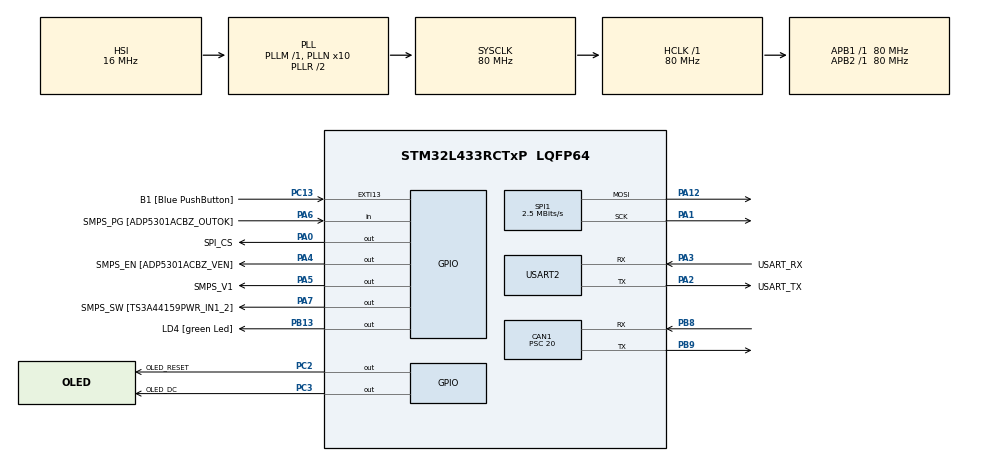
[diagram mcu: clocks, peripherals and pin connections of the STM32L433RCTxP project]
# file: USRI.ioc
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CAN1.BS1=CAN_BS1_14TQ
CAN1.CalculateBaudRate=250000
CAN1.CalculateTimeBit=4000.00
CAN1.CalculateTimeQuantum=250.0
CAN1.Prescaler=20
Mcu.Family=STM32L4
Mcu.Name=STM32L433RCTxP
Mcu.Package=LQFP64
NVIC.CAN1_RX0_IRQn=true\:0\:0\:false\:false\:true\:true\:true
NVIC.PriorityGroup=NVIC_PRIORITYGROUP_4
PA0.GPIO_Label=SPI_CS
PA0.Signal=GPIO_Output
PA1.Mode=TX_Only_Simplex_Unidirect_Master
PA1.Signal=SPI1_SCK
PA12.Mode=TX_Only_Simplex_Unidirect_Master
PA12.Signal=SPI1_MOSI
PA13\ (JTMS-SWDIO).GPIO_Label=TMS
PA13\ (JTMS-SWDIO).Mode=Serial_Wire
PA13\ (JTMS-SWDIO).Signal=SYS_JTMS-SWDIO
PA14\ (JTCK-SWCLK).GPIO_Label=TCK
PA14\ (JTCK-SWCLK).Mode=Serial_Wire
PA14\ (JTCK-SWCLK).Signal=SYS_JTCK-SWCLK
PA2.GPIO_Label=USART_TX
PA2.GPIO_Mode=GPIO_MODE_AF_PP
PA2.GPIO_PuPd=GPIO_NOPULL
PA2.GPIO_Speed=GPIO_SPEED_FREQ_VERY_HIGH
PA2.Mode=Asynchronous
PA2.Signal=USART2_TX
PA3.GPIO_Label=USART_RX
PA3.GPIO_Mode=GPIO_MODE_AF_PP
PA3.GPIO_PuPd=GPIO_NOPULL
PA3.GPIO_Speed=GPIO_SPEED_FREQ_VERY_HIGH
PA3.Mode=Asynchronous
PA3.Signal=USART2_RX
PA4.GPIO_Label=SMPS_EN [ADP5301ACBZ_VEN]
PA4.Signal=GPIO_Output
PA5.GPIO_Label=SMPS_V1
PA5.GPIO_ModeDefaultOutputPP=GPIO_MODE_OUTPUT_PP
PA5.GPIO_PuPd=GPIO_NOPULL
PA5.GPIO_Speed=GPIO_SPEED_FREQ_LOW
PA5.Signal=GPIO_Output
PA6.GPIO_Label=SMPS_PG [ADP5301ACBZ_OUTOK]
PA6.GPIO_PuPd=GPIO_PULLUP
PA6.Signal=GPIO_Input
PA7.GPIO_Label=SMPS_SW [TS3A44159PWR_IN1_2]
PA7.Signal=GPIO_Output
PB13.GPIO_Label=LD4 [green Led]
PB13.Signal=GPIO_Output
PB3\ (JTDO-TRACESWO).GPIO_Label=SWO
PB3\ (JTDO-TRACESWO).Signal=SYS_JTDO-SWO
PB8.Mode=CAN_Activate
PB8.Signal=CAN1_RX
PB9.Mode=CAN_Activate
PB9.Signal=CAN1_TX
PC13.GPIO_Label=B1 [Blue PushButton]
PC13.GPIO_ModeDefaultEXTI=GPIO_MODE_IT_FALLING
PC13.GPIO_PuPd=GPIO_NOPULL
PC13.Signal=GPXTI13
PC14-OSC32_IN\ (PC14).Mode=LSE-External-Oscillator
PC14-OSC32_IN\ (PC14).Signal=RCC_OSC32_IN
PC15-OSC32_OUT\ (PC15).Mode=LSE-External-Oscillator
PC15-OSC32_OUT\ (PC15).Signal=RCC_OSC32_OUT
PC2.GPIO_Label=OLED_RESET
PC2.Signal=GPIO_Output
PC3.GPIO_Label=OLED_DC
PC3.Signal=GPIO_Output
PH0-OSC_IN\ (PH0).GPIO_Label=MCO
PH0-OSC_IN\ (PH0).Mode=HSE-External-Clock-Source
PH0-OSC_IN\ (PH0).Signal=RCC_OSC_IN
PH1-OSC_OUT\ (PH1).Signal=RCC_OSC_OUT
ProjectManager.HeapSize=0x200
ProjectManager.StackSize=0x400
ProjectManager.TargetToolchain=STM32CubeIDE
RCC.ADCFreq_Value=64000000
RCC.AHBFreq_Value=80000000
RCC.APB1Freq_Value=80000000
RCC.APB1TimFreq_Value=80000000
RCC.APB2Freq_Value=80000000
RCC.APB2TimFreq_Value=80000000
RCC.CortexFreq_Value=80000000
RCC.HCLKFreq_Value=80000000
RCC.HSE_VALUE=8000000
RCC.HSI48_VALUE=48000000
RCC.HSI_VALUE=16000000
RCC.MSI_VALUE=4000000
RCC.PLLN=10
RCC.PLLSourceVirtual=RCC_PLLSOURCE_HSI
RCC.PREFETCH_ENABLE=1
RCC.SYSCLKFreq_VALUE=80000000
RCC.SYSCLKSource=RCC_SYSCLKSOURCE_PLLCLK
RCC.USBFreq_Value=64000000
RCC.VCOOutputFreq_Value=160000000
SPI1.BaudRatePrescaler=SPI_BAUDRATEPRESCALER_32
SPI1.CLKPhase=SPI_PHASE_2EDGE
SPI1.CLKPolarity=SPI_POLARITY_HIGH
SPI1.CalculateBaudRate=2.5 MBits/s
SPI1.Direction=SPI_DIRECTION_2LINES
SPI1.Mode=SPI_MODE_MASTER
SPI1.VirtualType=VM_MASTER
USART2.VirtualMode-Asynchronous=VM_ASYNC
board=NUCLEO-L433RC-P

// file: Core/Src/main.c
/* USER CODE BEGIN Header */
/**
  ******************************************************************************
  * @file           : main.c
  * @brief          : Main program body
  ******************************************************************************
  * @attention
  *
  * <h2><center>&copy; Copyright (c) 2021 STMicroelectronics.
  * All rights reserved.</center></h2>
  *
  * This software component is licensed by ST under BSD 3-Clause license,
  * the "License"; You may not use this file except in compliance with the
  * License. You may obtain a copy of the License at:
  *                        opensource.org/licenses/BSD-3-Clause
  *
  ******************************************************************************
  */
/* USER CODE END Header */
#include "main.h"
#include "can.h"
#include "spi.h"
#include "usart.h"
#include "gpio.h"

/* USER CODE BEGIN Includes */
#include "CAN_API.h"
#include "OLED_Interface.h"
#include "CAN_Utils.h"
#include "stdio.h"
#include <string.h>
#include "SSD1322_API.h"
#include "SSD1322_HW_Driver.h"
/* USER CODE END Includes */

/* USER CODE BEGIN PTD */
CAN_RX_message *rx_msg_ptr;
message_t parsed_ID;

OLED_t screen_1;
OLED_t screen_2;

/* USER CODE END PTD */

void SystemClock_Config(void);
/* USER CODE BEGIN PFP */
//void CAN_Handler(message_t *parsed_ID);
//uint8_t get_data_counter(CAN_RX_message *rx_msg_ptr);

/* USER CODE END PFP */

int main(void)
{

  /* MCU Configuration--------------------------------------------------------*/

  /* Reset of all peripherals, Initializes the Flash interface and the Systick. */
  HAL_Init();

  /* Configure the system clock */
  SystemClock_Config();

  /* Initialize all configured peripherals */
  MX_GPIO_Init();
  MX_USART2_UART_Init();
  MX_CAN1_Init();
  MX_SPI1_Init();
  /* USER CODE BEGIN 2 */
  CAN_init(&hcan1);
  /* USER CODE END 2 */

  /* Infinite loop */
  /* USER CODE BEGIN WHILE */
  while (1)
  {
	  //HAL_Delay(2000);
	  CAN_Handler(&parsed_ID);

	  // TODO: Add screen instances as arguments
	  Interface_Handler(&parsed_ID);

    /* USER CODE END WHILE */

  }
}

void SystemClock_Config(void)
{
  RCC_OscInitTypeDef RCC_OscInitStruct = {0};
  RCC_ClkInitTypeDef RCC_ClkInitStruct = {0};

  /** Configure the main internal regulator output voltage
  */
  if (HAL_PWREx_ControlVoltageScaling(PWR_REGULATOR_VOLTAGE_SCALE1) != HAL_OK)
  {
    Error_Handler();
  }
  /** Initializes the RCC Oscillators according to the specified parameters
  * in the RCC_OscInitTypeDef structure.
  */
  RCC_OscInitStruct.OscillatorType = RCC_OSCILLATORTYPE_HSI;
  RCC_OscInitStruct.HSIState = RCC_HSI_ON;
  RCC_OscInitStruct.HSICalibrationValue = RCC_HSICALIBRATION_DEFAULT;
  RCC_OscInitStruct.PLL.PLLState = RCC_PLL_ON;
  RCC_OscInitStruct.PLL.PLLSource = RCC_PLLSOURCE_HSI;
  RCC_OscInitStruct.PLL.PLLM = 1;
  RCC_OscInitStruct.PLL.PLLN = 10;
  RCC_OscInitStruct.PLL.PLLP = RCC_PLLP_DIV7;
  RCC_OscInitStruct.PLL.PLLQ = RCC_PLLQ_DIV2;
  RCC_OscInitStruct.PLL.PLLR = RCC_PLLR_DIV2;
  if (HAL_RCC_OscConfig(&RCC_OscInitStruct) != HAL_OK)
  {
    Error_Handler();
  }
  /** Initializes the CPU, AHB and APB buses clocks
  */
  RCC_ClkInitStruct.ClockType = RCC_CLOCKTYPE_HCLK|RCC_CLOCKTYPE_SYSCLK
                              |RCC_CLOCKTYPE_PCLK1|RCC_CLOCKTYPE_PCLK2;
  RCC_ClkInitStruct.SYSCLKSource = RCC_SYSCLKSOURCE_PLLCLK;
  RCC_ClkInitStruct.AHBCLKDivider = RCC_SYSCLK_DIV1;
  RCC_ClkInitStruct.APB1CLKDivider = RCC_HCLK_DIV1;
  RCC_ClkInitStruct.APB2CLKDivider = RCC_HCLK_DIV1;

  if (HAL_RCC_ClockConfig(&RCC_ClkInitStruct, FLASH_LATENCY_4) != HAL_OK)
  {
    Error_Handler();
  }
}

void Error_Handler(void)
{
  __disable_irq();
  while (1)
  {
  }
}

/************************ (C) COPYRIGHT STMicroelectronics *****END OF FILE****/
